VERSION "0.1"

NS_ :

BU_: PC

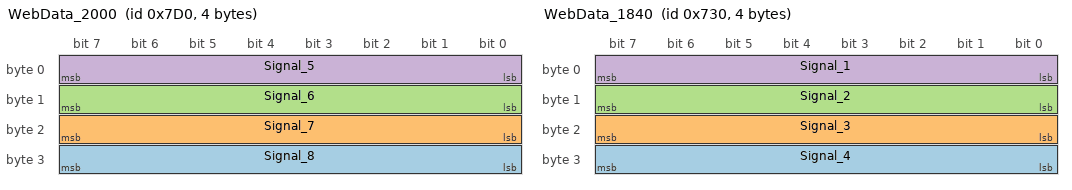
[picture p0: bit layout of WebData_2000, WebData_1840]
BO_ 2000 WebData_2000: 4 Vector__XXX
    SG_ Signal_8 : 24|8@1+ (1,0) [0|255] "" Vector__XXX
    SG_ Signal_7 : 16|8@1+ (1,0) [0|255] "" Vector__XXX
    SG_ Signal_6 : 8|8@1+ (1,0) [0|255] "" Vector__XXX
    SG_ Signal_5 : 0|8@1+ (1,0) [0|255] "" Vector__XXX

BO_ 1840 WebData_1840: 4 PC
    SG_ Signal_4 : 24|8@1+ (1,0) [0|255] "" Vector__XXX
    SG_ Signal_3 : 16|8@1+ (1,0) [0|255] "" Vector__XXX
    SG_ Signal_2 : 8|8@1+ (1,0) [0|255] "" Vector__XXX
    SG_ Signal_1 : 0|8@1+ (1,0) [0|0] "" Vector__XXX

EV_ Environment1: 0 [0|220] "" 0 6 DUMMY_NODE_VECTOR0 DUMMY_NODE_VECTOR2;

EV_ Environment2: 0 [0|177] "" 0 7 DUMMY_NODE_VECTOR1 DUMMY_NODE_VECTOR2;

ENVVAR_DATA_ SomeEnvVarData: 399;

CM_ SG_ 4 TestSigLittleUnsigned1 "asaklfjlsdfjlsdfgls
HH?=(%)/&KKDKFSDKFKDFKSDFKSDFNKCnvsdcvsvxkcv";
CM_ SG_ 5 TestSigLittleUnsigned1 "asaklfjlsdfjlsdfgls
=0943503450KFSDKFKDFKSDFKSDFNKCnvsdcvsvxkcv";

BA_DEF_DEF_ "BusType" "AS";

BA_ "Attr" BO_ 4358435 283;
BA_ "Attr" BO_ 56949545 344;

VAL_ 3454 TestValue 3423232 "positive" 359595 "doe" -1393 "john" ;
VAL_ 3454 TestValue 3423232 "positive" 359595 "doe" -1393 "positive" 359595 "doe" -1393 "john" ;
